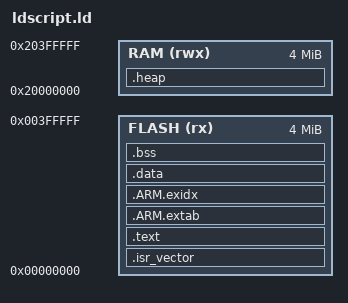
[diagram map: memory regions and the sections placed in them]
MEMORY
{
  FLASH (rx) : ORIGIN = 0x00000000, LENGTH = 0x00400000
  RAM (rwx) : ORIGIN = 0x20000000, LENGTH = 0x00400000
}
ENTRY(Reset_Handler)
STACK_SIZE = 0x400;
M_VECTOR_RAM_SIZE = ((16 + 48) * 4);
SECTIONS
{
    .isr_vector :
    {
        __vector_table = .;
        KEEP(*(.vector_table))
         . = ALIGN(8);
    } > FLASH
    .text :
    {
        . = ALIGN(8);
        *(.text*)
        KEEP(*(.init))
        KEEP(*(.fini))
        *crtbegin.o(.ctors)
        *crtbegin?.o(.ctors)
        *(EXCLUDE_FILE(*crtend?.o *crtend.o) .ctors)
        *(SORT(.ctors.*))
        *(.ctors)
        *crtbegin.o(.dtors)
        *crtbegin?.o(.dtors)
        *(EXCLUDE_FILE(*crtend?.o *crtend.o) .dtors)
        *(SORT(.dtors.*))
        *(.dtors)
        *(.rodata*)
        KEEP(*(.eh_frame*))
    } > FLASH
    .ARM.extab :
    {
        *(.ARM.extab* .gnu.linkonce.armextab.*)
    } > FLASH
    __exidx_start = .;
    .ARM.exidx :
    {
        *(.ARM.exidx* .gnu.linkonce.armexidx.*)
    } > FLASH
    __exidx_end = .;
    .data :
    {
        __data_start__ = .;
        *(vtable)
        *(.data)
        *(.data*)
        . = ALIGN(8);
        PROVIDE (__preinit_array_start = .);
        KEEP(*(.preinit_array))
        PROVIDE (__preinit_array_end = .);
        . = ALIGN(8);
        PROVIDE (__init_array_start = .);
        KEEP(*(SORT(.init_array.*)))
        KEEP(*(.init_array))
        PROVIDE (__init_array_end = .);
        . = ALIGN(8);
        PROVIDE (__fini_array_start = .);
        KEEP(*(SORT(.fini_array.*)))
        KEEP(*(.fini_array))
        PROVIDE (__fini_array_end = .);
        . = ALIGN(8);
        __data_end__ = .;
    } > FLASH
    .bss :
    {
        . = ALIGN(8);
        __START_BSS = .;
        __bss_start__ = .;
        *(.bss)
        *(.bss*)
        *(COMMON)
        . = ALIGN(8);
        __bss_end__ = .;
        __END_BSS = .;
    } > FLASH
    bss_size = __bss_end__ - __bss_start__;
    .heap (COPY):
    {
        . = ALIGN(8);
        __end__ = .;
        PROVIDE(end = .);
        __HeapBase = .;
        *(.heap*)
        . = ORIGIN(RAM) + LENGTH(RAM) - STACK_SIZE;
        __HeapLimit = .;
        __heap_limit = .;
    } > RAM
    __StackTop = ORIGIN(RAM) + LENGTH(RAM);
    __StackLimit = __StackTop - STACK_SIZE;
    PROVIDE(__stack = __StackTop);
    ASSERT(__StackLimit >= __HeapLimit, "region RAM overflowed with stack")
}
